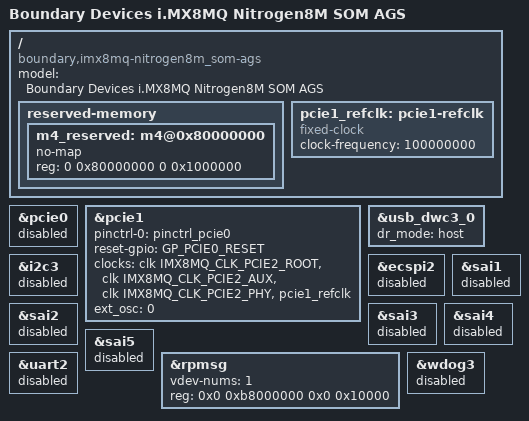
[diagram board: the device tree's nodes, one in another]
// SPDX-License-Identifier: (GPL-2.0+ OR MIT)
/*
 * Copyright 2020 Boundary Devices
 */

#include "imx8mq-nitrogen8m_som_sd.dts"

/ {
	model = "Boundary Devices i.MX8MQ Nitrogen8M SOM AGS";
	compatible = "boundary,imx8mq-nitrogen8m_som-ags", "fsl,imx8mq";

	reserved-memory {
		#address-cells = <2>;
		#size-cells = <2>;
		ranges;

		m4_reserved: m4@0x80000000 {
			no-map;
			reg = <0 0x80000000 0 0x1000000>;
		};

	};

	pcie1_refclk: pcie1-refclk {
		compatible = "fixed-clock";
		#clock-cells = <0>;
		clock-frequency = <100000000>;
	};
};

&pcie0 {
	status = "disabled";
};

&pcie1 {
	/delete-property/ hard-wired;
	pinctrl-names = "default";
	pinctrl-0 = <&pinctrl_pcie0>;
	reset-gpio = GP_PCIE0_RESET;
	clocks = <&clk IMX8MQ_CLK_PCIE2_ROOT>,
		<&clk IMX8MQ_CLK_PCIE2_AUX>,
		<&clk IMX8MQ_CLK_PCIE2_PHY>,
		<&pcie1_refclk>;
	clock-names = "pcie", "pcie_bus", "pcie_phy", "pcie_ext_src";
	ext_osc = <0>;
	status = "okay";
};

&usb_dwc3_0 {
	dr_mode = "host";
};

&ecspi2 {
	status = "disabled";
};

&i2c3 {
	status = "disabled";
};

&sai1 {
	status = "disabled";
};

&sai2 {
	status = "disabled";
};

&sai3 {
	status = "disabled";
};

&sai4 {
	status = "disabled";
};

&sai5 {
	status = "disabled";
};

&rpmsg{
	/*
	 * 64K for one rpmsg instance:
	 * --0xb8000000~0xb800ffff: pingpong
	 */
	vdev-nums = <1>;
	reg = <0x0 0xb8000000 0x0 0x10000>;
	status = "okay";
};

&uart2 {
	status = "disabled";
};

&wdog3{
	status = "disabled";
};
